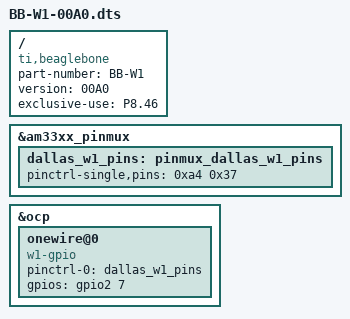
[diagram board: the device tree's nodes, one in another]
/dts-v1/;
/plugin/; 

/ {
    compatible = "ti,beaglebone", "ti,beaglebone-black";
    part-number = "BB-W1";
    version = "00A0"; 

    /* state the resources this cape uses */
    exclusive-use =
        /* the pin header uses */
        "P8.46";
        /* the hardware IP uses */
        //"gpio1_28"; 

    fragment@0 {
               target = <&am33xx_pinmux>;
               __overlay__ {
                    dallas_w1_pins: pinmux_dallas_w1_pins {
                        pinctrl-single,pins = <0xa4 0x37>;
                    };
               };
    }; 

    fragment@1 {
               target = <&ocp>;
               __overlay__ {
               onewire@0 {
                   compatible      = "w1-gpio";
                   pinctrl-names   = "default";
                   pinctrl-0       = <&dallas_w1_pins>;
                   status          = "okay"; 

                   //gpios = <&gpio1 28 0>;
                   gpios = <&gpio2 7 0>;
               };
         };
    };
};
